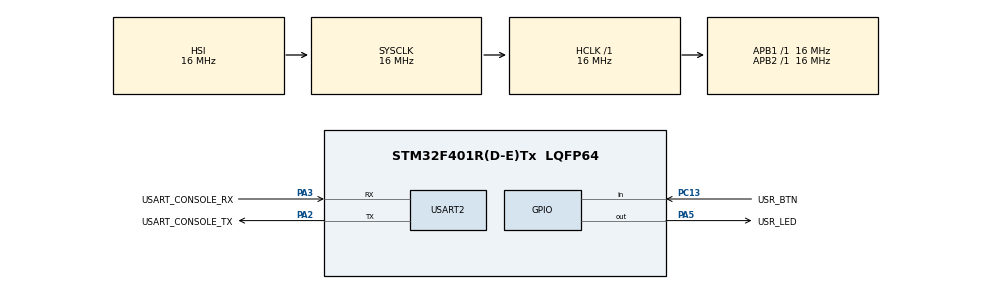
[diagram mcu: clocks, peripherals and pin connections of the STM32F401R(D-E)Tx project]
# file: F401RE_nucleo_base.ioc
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FREERTOS.Tasks01=blink01,24,128,StartBlink01,Default,NULL,Dynamic,NULL,NULL;blink02,16,128,StartBlink02,Default,NULL,Dynamic,NULL,NULL;ConsoleTask,8,128,StartConsoleTask,Default,NULL,Dynamic,NULL,NULL
Mcu.Family=STM32F4
Mcu.Name=STM32F401R(D-E)Tx
Mcu.Package=LQFP64
NVIC.PriorityGroup=NVIC_PRIORITYGROUP_4
NVIC.TIM4_IRQn=true\:0\:0\:false\:false\:true\:false\:false\:true
NVIC.TimeBase=TIM4_IRQn
NVIC.TimeBaseIP=TIM4
PA2.GPIO_Label=USART_CONSOLE_TX
PA2.Mode=Asynchronous
PA2.Signal=USART2_TX
PA3.GPIO_Label=USART_CONSOLE_RX
PA3.Mode=Asynchronous
PA3.Signal=USART2_RX
PA5.GPIO_Label=USR_LED
PA5.Signal=GPIO_Output
PC13-ANTI_TAMP.GPIO_Label=USR_BTN
PC13-ANTI_TAMP.Signal=GPIO_Input
ProjectManager.HeapSize=0x200
ProjectManager.StackSize=0x400
ProjectManager.TargetToolchain=STM32CubeIDE
RCC.AHBFreq_Value=16000000
RCC.APB1Freq_Value=16000000
RCC.APB2Freq_Value=16000000
RCC.CortexFreq_Value=16000000
RCC.HSE_VALUE=25000000
RCC.HSI_VALUE=16000000
RCC.LSE_VALUE=32768
RCC.SYSCLKFreq_VALUE=16000000
RCC.VCOOutputFreq_Value=192000000
USART2.VirtualMode=VM_ASYNC
VP_FREERTOS_VS_CMSIS_V2.Mode=CMSIS_V2
VP_SYS_VS_tim4.Mode=TIM4
board=custom

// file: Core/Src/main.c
/* USER CODE BEGIN Header */
/**
  ******************************************************************************
  * @file           : main.c
  * @brief          : Main program body
  ******************************************************************************
  * @attention
  *
  * <h2><center>&copy; Copyright (c) 2020 STMicroelectronics.
  * All rights reserved.</center></h2>
  *
  * This software component is licensed by ST under BSD 3-Clause license,
  * the "License"; You may not use this file except in compliance with the
  * License. You may obtain a copy of the License at:
  *                        opensource.org/licenses/BSD-3-Clause
  *
  ******************************************************************************
  */
/* USER CODE END Header */

#include "main.h"
#include "cmsis_os.h"

/* USER CODE BEGIN Includes */
#include "command_line_task.h"
/* USER CODE END Includes */

UART_HandleTypeDef huart2;

/* Definitions for blink01 */
osThreadId_t blink01Handle;
const osThreadAttr_t blink01_attributes = {
  .name = "blink01",
  .priority = (osPriority_t) osPriorityNormal,
  .stack_size = 128
};
/* Definitions for blink02 */
osThreadId_t blink02Handle;
const osThreadAttr_t blink02_attributes = {
  .name = "blink02",
  .priority = (osPriority_t) osPriorityBelowNormal,
  .stack_size = 128
};
/* Definitions for ConsoleTask */
osThreadId_t ConsoleTaskHandle;
const osThreadAttr_t ConsoleTask_attributes = {
  .name = "ConsoleTask",
  .priority = (osPriority_t) osPriorityLow,
  .stack_size = 128
};

void SystemClock_Config(void);
static void MX_GPIO_Init(void);
static void MX_USART2_UART_Init(void);
void StartBlink01(void *argument);
void StartBlink02(void *argument);
void StartConsoleTask(void *argument);

int main(void)
{

  /* MCU Configuration--------------------------------------------------------*/

  /* Reset of all peripherals, Initializes the Flash interface and the Systick. */
  HAL_Init();

  /* Configure the system clock */
  SystemClock_Config();

  /* Initialize all configured peripherals */
  MX_GPIO_Init();
  MX_USART2_UART_Init();
  /* Init scheduler */
  osKernelInitialize();

  /* Create the thread(s) */
  /* creation of blink01 */
  blink01Handle = osThreadNew(StartBlink01, NULL, &blink01_attributes);

  /* creation of blink02 */
  blink02Handle = osThreadNew(StartBlink02, NULL, &blink02_attributes);

  /* creation of ConsoleTask */
  ConsoleTaskHandle = osThreadNew(StartConsoleTask, NULL, &ConsoleTask_attributes);

  /* Start scheduler */
  osKernelStart();

  /* We should never get here as control is now taken by the scheduler */

  /* Infinite loop */
  while (1)
  {

  }
}

void SystemClock_Config(void)
{
  RCC_OscInitTypeDef RCC_OscInitStruct = {0};
  RCC_ClkInitTypeDef RCC_ClkInitStruct = {0};

  /** Configure the main internal regulator output voltage
  */
  __HAL_RCC_PWR_CLK_ENABLE();
  __HAL_PWR_VOLTAGESCALING_CONFIG(PWR_REGULATOR_VOLTAGE_SCALE2);
  /** Initializes the CPU, AHB and APB busses clocks
  */
  RCC_OscInitStruct.OscillatorType = RCC_OSCILLATORTYPE_HSI;
  RCC_OscInitStruct.HSIState = RCC_HSI_ON;
  RCC_OscInitStruct.HSICalibrationValue = RCC_HSICALIBRATION_DEFAULT;
  RCC_OscInitStruct.PLL.PLLState = RCC_PLL_NONE;
  if (HAL_RCC_OscConfig(&RCC_OscInitStruct) != HAL_OK)
  {
    Error_Handler();
  }
  /** Initializes the CPU, AHB and APB busses clocks
  */
  RCC_ClkInitStruct.ClockType = RCC_CLOCKTYPE_HCLK|RCC_CLOCKTYPE_SYSCLK
                              |RCC_CLOCKTYPE_PCLK1|RCC_CLOCKTYPE_PCLK2;
  RCC_ClkInitStruct.SYSCLKSource = RCC_SYSCLKSOURCE_HSI;
  RCC_ClkInitStruct.AHBCLKDivider = RCC_SYSCLK_DIV1;
  RCC_ClkInitStruct.APB1CLKDivider = RCC_HCLK_DIV1;
  RCC_ClkInitStruct.APB2CLKDivider = RCC_HCLK_DIV1;

  if (HAL_RCC_ClockConfig(&RCC_ClkInitStruct, FLASH_LATENCY_0) != HAL_OK)
  {
    Error_Handler();
  }
}

static void MX_USART2_UART_Init(void)
{

  huart2.Instance = USART2;
  huart2.Init.BaudRate = 115200;
  huart2.Init.WordLength = UART_WORDLENGTH_8B;/*
   * command_line_task.h
   *
   *  Created on: Feb 10, 2020
   *      Author: s3rf
   */

  #ifndef INC_COMMAND_LINE_TASK_H_
  #define INC_COMMAND_LINE_TASK_H_

  #endif /* INC_COMMAND_LINE_TASK_H_ */

  huart2.Init.StopBits = UART_STOPBITS_1;
  huart2.Init.Parity = UART_PARITY_NONE;
  huart2.Init.Mode = UART_MODE_TX_RX;
  huart2.Init.HwFlowCtl = UART_HWCONTROL_NONE;
  huart2.Init.OverSampling = UART_OVERSAMPLING_16;
  if (HAL_UART_Init(&huart2) != HAL_OK)
  {
    Error_Handler();
  }

}

static void MX_GPIO_Init(void)
{
  GPIO_InitTypeDef GPIO_InitStruct = {0};

  /* GPIO Ports Clock Enable */
  __HAL_RCC_GPIOC_CLK_ENABLE();
  __HAL_RCC_GPIOA_CLK_ENABLE();

  /*Configure GPIO pin Output Level */
  HAL_GPIO_WritePin(USR_LED_GPIO_Port, USR_LED_Pin, GPIO_PIN_RESET);

  /*Configure GPIO pin : USR_BTN_Pin */
  GPIO_InitStruct.Pin = USR_BTN_Pin;
  GPIO_InitStruct.Mode = GPIO_MODE_INPUT;
  GPIO_InitStruct.Pull = GPIO_NOPULL;
  HAL_GPIO_Init(USR_BTN_GPIO_Port, &GPIO_InitStruct);

  /*Configure GPIO pin : USR_LED_Pin */
  GPIO_InitStruct.Pin = USR_LED_Pin;
  GPIO_InitStruct.Mode = GPIO_MODE_OUTPUT_PP;
  GPIO_InitStruct.Pull = GPIO_NOPULL;
  GPIO_InitStruct.Speed = GPIO_SPEED_FREQ_LOW;
  HAL_GPIO_Init(USR_LED_GPIO_Port, &GPIO_InitStruct);

}

void StartBlink01(void *argument)
{
  /* USER CODE BEGIN 5 */
  /* Infinite loop */
  for(;;)
  {
	  HAL_GPIO_TogglePin(GPIOA, GPIO_PIN_5);
	  osDelay(500);
  }
  //We should never be here unless there is cause to terminate
    osThreadTerminate(NULL);
  /* USER CODE END 5 */
}

void StartBlink02(void *argument)
{
  /* USER CODE BEGIN StartBlink02 */
  /* Infinite loop */
  for(;;)
  {
	  HAL_GPIO_TogglePin(GPIOA, GPIO_PIN_5);
	  osDelay(600);
  }
  //We should never be here unless there is cause to terminate
  osThreadTerminate(NULL);
  /* USER CODE END StartBlink02 */
}

void StartConsoleTask(void *argument)
{
  /* USER CODE BEGIN StartConsoleTask */
  /* Infinite loop */
  cliTask();

  /*Code should Never Reach THis point*/
  osThreadTerminate(NULL);

  /* USER CODE END StartConsoleTask */
}

void HAL_TIM_PeriodElapsedCallback(TIM_HandleTypeDef *htim)
{
  if (htim->Instance == TIM4) {
    HAL_IncTick();
  }
}

void Error_Handler(void)
{
}

/************************ (C) COPYRIGHT STMicroelectronics *****END OF FILE****/
